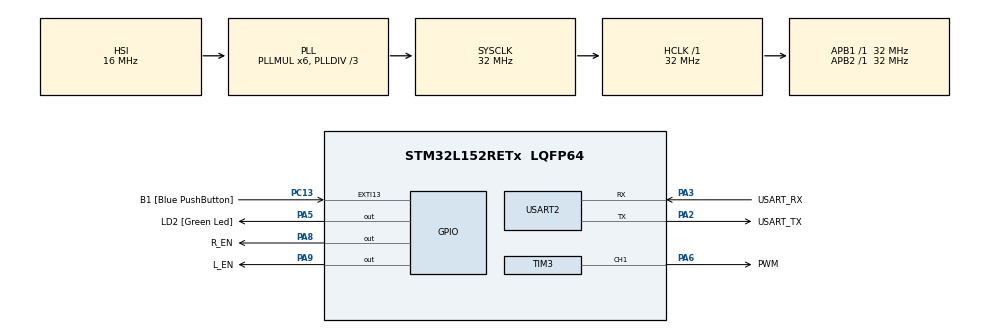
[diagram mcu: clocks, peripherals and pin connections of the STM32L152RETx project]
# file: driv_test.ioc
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Mcu.Family=STM32L1
Mcu.Name=STM32L152RETx
Mcu.Package=LQFP64
NVIC.PriorityGroup=NVIC_PRIORITYGROUP_0
PA13.GPIO_Label=TMS
PA13.Mode=Serial_Wire
PA13.Signal=SYS_JTMS-SWDIO
PA14.GPIO_Label=TCK
PA14.Mode=Serial_Wire
PA14.Signal=SYS_JTCK-SWCLK
PA2.GPIO_Label=USART_TX
PA2.Mode=Asynchronous
PA2.Signal=USART2_TX
PA3.GPIO_Label=USART_RX
PA3.Mode=Asynchronous
PA3.Signal=USART2_RX
PA5.GPIO_Label=LD2 [Green Led]
PA5.Signal=GPIO_Output
PA6.GPIO_Label=PWM
PA6.Signal=S_TIM3_CH1
PA8.GPIO_Label=R_EN
PA8.Signal=GPIO_Output
PA9.GPIO_Label=L_EN
PA9.Signal=GPIO_Output
PB3.GPIO_Label=SWO
PB3.Signal=SYS_JTDO-TRACESWO
PC13-WKUP2.GPIO_Label=B1 [Blue PushButton]
PC13-WKUP2.Signal=GPXTI13
PC14-OSC32_IN.Mode=LSE-External-Oscillator
PC14-OSC32_IN.Signal=RCC_OSC32_IN
PC15-OSC32_OUT.Mode=LSE-External-Oscillator
PC15-OSC32_OUT.Signal=RCC_OSC32_OUT
PH0-OSC_IN.Mode=HSE-External-Clock-Source
PH0-OSC_IN.Signal=RCC_OSC_IN
PH1-OSC_OUT.Signal=RCC_OSC_OUT
ProjectManager.HeapSize=0x200
ProjectManager.StackSize=0x400
ProjectManager.TargetToolchain=STM32CubeIDE
RCC.48MHZClocksFreq_Value=48000000
RCC.AHBFreq_Value=32000000
RCC.APB1Freq_Value=32000000
RCC.APB1TimFreq_Value=32000000
RCC.APB2Freq_Value=32000000
RCC.APB2TimFreq_Value=32000000
RCC.HCLKFreq_Value=32000000
RCC.HSE_VALUE=8000000
RCC.HSI_VALUE=16000000
RCC.MSI_VALUE=2097000
RCC.PLLDIV=RCC_PLL_DIV3
RCC.PLLMUL=RCC_PLL_MUL6
RCC.RTCClockSelectionVirtual=RCC_RTCCLKSOURCE_LSE
RCC.SYSCLKFreq_VALUE=32000000
RCC.SYSCLKSource=RCC_SYSCLKSOURCE_PLLCLK
RCC.USBOutput=48000000
RCC.VCOOutputFreq_Value=96000000
SH.S_TIM3_CH1.0=TIM3_CH1,PWM Generation1 CH1
TIM3.Channel-PWM\ Generation1\ CH1=TIM_CHANNEL_1
TIM3.Period=999
TIM3.Prescaler=3
USART2.VirtualMode=VM_ASYNC
VP_TIM3_VS_ClockSourceINT.Mode=Internal
board=NUCLEO-L152RE

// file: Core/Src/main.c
/* USER CODE BEGIN Header */
/**
  ******************************************************************************
  * @file           : main.c
  * @brief          : Main program body
  ******************************************************************************
  * @attention
  *
  * Copyright (c) 2023 STMicroelectronics.
  * All rights reserved.
  *
  * This software is licensed under terms that can be found in the LICENSE file
  * in the root directory of this software component.
  * If no LICENSE file comes with this software, it is provided AS-IS.
  *
  ******************************************************************************
  */
/* USER CODE END Header */
#include "main.h"
#include "tim.h"
#include "usart.h"
#include "gpio.h"

void SystemClock_Config(void);

int main(void)
{

  /* MCU Configuration--------------------------------------------------------*/

  /* Reset of all peripherals, Initializes the Flash interface and the Systick. */
  HAL_Init();

  /* Configure the system clock */
  SystemClock_Config();

  /* Initialize all configured peripherals */
  MX_GPIO_Init();
  MX_USART2_UART_Init();
  MX_TIM3_Init();
  HAL_TIM_PWM_Start(&htim3, TIM_CHANNEL_1);
  /* USER CODE BEGIN 2 */
  __HAL_TIM_SET_COMPARE(&htim3, TIM_CHANNEL_1, 1000);
  /* USER CODE END 2 */

  /* Infinite loop */
  while (1)
  {
	  HAL_GPIO_WritePin(L_EN_GPIO_Port, L_EN_Pin, GPIO_PIN_RESET);
	  HAL_GPIO_WritePin(R_EN_GPIO_Port, R_EN_Pin, GPIO_PIN_SET);
	  HAL_Delay(2000);
	  HAL_GPIO_WritePin(R_EN_GPIO_Port, R_EN_Pin, GPIO_PIN_RESET);
	  HAL_GPIO_WritePin(L_EN_GPIO_Port, L_EN_Pin, GPIO_PIN_SET);
	  HAL_Delay(2000);
  }
}

void SystemClock_Config(void)
{
  RCC_OscInitTypeDef RCC_OscInitStruct = {0};
  RCC_ClkInitTypeDef RCC_ClkInitStruct = {0};

  /** Configure the main internal regulator output voltage
  */
  __HAL_PWR_VOLTAGESCALING_CONFIG(PWR_REGULATOR_VOLTAGE_SCALE1);

  /** Initializes the RCC Oscillators according to the specified parameters
  * in the RCC_OscInitTypeDef structure.
  */
  RCC_OscInitStruct.OscillatorType = RCC_OSCILLATORTYPE_HSI;
  RCC_OscInitStruct.HSIState = RCC_HSI_ON;
  RCC_OscInitStruct.HSICalibrationValue = RCC_HSICALIBRATION_DEFAULT;
  RCC_OscInitStruct.PLL.PLLState = RCC_PLL_ON;
  RCC_OscInitStruct.PLL.PLLSource = RCC_PLLSOURCE_HSI;
  RCC_OscInitStruct.PLL.PLLMUL = RCC_PLL_MUL6;
  RCC_OscInitStruct.PLL.PLLDIV = RCC_PLL_DIV3;
  if (HAL_RCC_OscConfig(&RCC_OscInitStruct) != HAL_OK)
  {
    Error_Handler();
  }

  /** Initializes the CPU, AHB and APB buses clocks
  */
  RCC_ClkInitStruct.ClockType = RCC_CLOCKTYPE_HCLK|RCC_CLOCKTYPE_SYSCLK
                              |RCC_CLOCKTYPE_PCLK1|RCC_CLOCKTYPE_PCLK2;
  RCC_ClkInitStruct.SYSCLKSource = RCC_SYSCLKSOURCE_PLLCLK;
  RCC_ClkInitStruct.AHBCLKDivider = RCC_SYSCLK_DIV1;
  RCC_ClkInitStruct.APB1CLKDivider = RCC_HCLK_DIV1;
  RCC_ClkInitStruct.APB2CLKDivider = RCC_HCLK_DIV1;

  if (HAL_RCC_ClockConfig(&RCC_ClkInitStruct, FLASH_LATENCY_1) != HAL_OK)
  {
    Error_Handler();
  }
}

void Error_Handler(void)
{
  __disable_irq();
  while (1)
  {
  }
}
